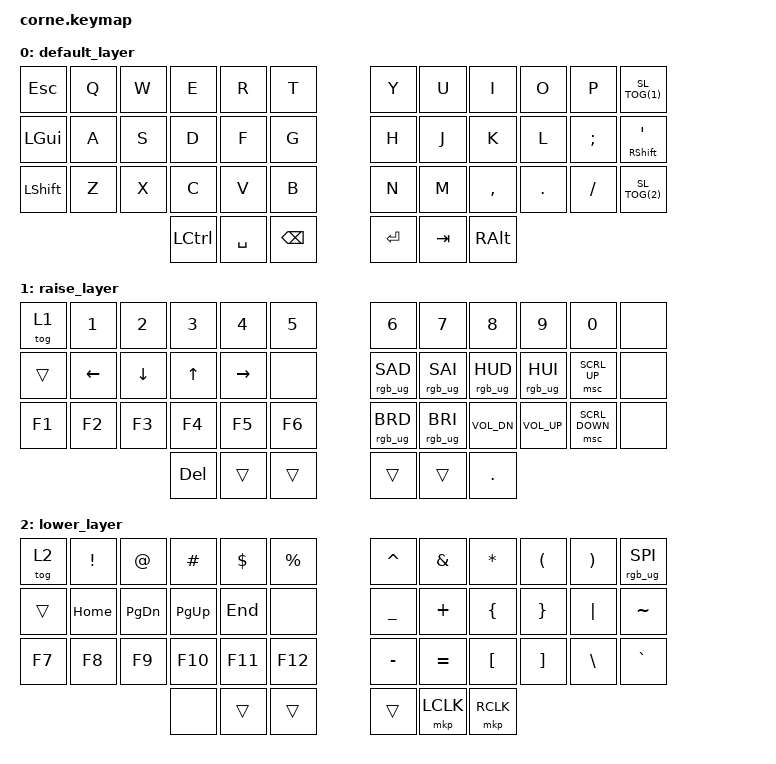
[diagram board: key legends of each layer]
/*
 * Copyright (c) 2020 The ZMK Contributors
 *
 * SPDX-License-Identifier: MIT
 */

#include <behaviors.dtsi>
#include <dt-bindings/zmk/keys.h>
#include <dt-bindings/zmk/bt.h>
#include <dt-bindings/zmk/rgb.h>
#include <dt-bindings/zmk/pointing.h>

#define SL_TOG(layer) &sl_tog layer layer // Macro for "sticky layer" on tap "tog layer" on hold

&mt {
    tapping-term-ms = <250>;
};

&sl {
    release-after-ms = <2000>;
};

&led_strip {
    chain-length = <27>;
};

/ {
    behaviors {
        sl_tog: behavior_sl_tog {
            compatible = "zmk,behavior-hold-tap";
            #binding-cells = <2>;
            flavor = "tap-preferred";
            tapping-term-ms = <300>;
            bindings = <&tog>, <&sl>;
        };
    };

    keymap {
        compatible = "zmk,keymap";

// -----------------------------------------------------------------------------------
// |  ESC |  Q  |  W  |  E  |  R  |  T  |   |  Y  |  U  |  I  |  O  |  P  | L1       |
// |  GUI |  A  |  S  |  D  |  F  |  G  |   |  H  |  J  |  K  |  L  |  ;  | ' > SHFT |
// | SHFT |  Z  |  X  |  C  |  V  |  B  |   |  N  |  M  |  ,  |  .  |  /  | L2       |
//                    | CTL | SPC | BSP |   | ENT | TAB | ALT |
        default_layer { bindings = <
    &kp ESC   &kp Q &kp W &kp E     &kp R     &kp T      &kp Y     &kp U   &kp I     &kp O   &kp P    SL_TOG(1)
    &kp LGUI  &kp A &kp S &kp D     &kp F     &kp G      &kp H     &kp J   &kp K     &kp L   &kp SEMI &mt RSHFT SQT
    &kp LSHFT &kp Z &kp X &kp C     &kp V     &kp B      &kp N     &kp M   &kp COMMA &kp DOT &kp FSLH SL_TOG(2)
                          &kp LCTRL &kp SPACE &kp BSPC   &kp ENTER &kp TAB &kp RALT
        >; };

// -----------------------------------------------------------------------------
// | L0 |  1  |  2  |  3  |  4  |  5  |   |  6  |  7  |  8  |  9  |  0  | xxx |
// |    | LFT | DWN | UP  | RGT | xxx |   | SAD | SAI | HUD | HUI | SCU | xxx |
// | F1 | F2  | F3  | F4  | F5  | F6  |   | BRD | BRI | VDN | VUP | SCD | xxx |
//                  | DEL |     |     |   |     |     |  .  |
        raise_layer { bindings = <
    &tog 1 &kp N1   &kp N2   &kp N3  &kp N4    &kp N5 &kp N6          &kp N7          &kp N8          &kp N9          &kp N0         &none
    &trans &kp LEFT &kp DOWN &kp UP  &kp RIGHT &none  &rgb_ug RGB_SAD &rgb_ug RGB_SAI &rgb_ug RGB_HUD &rgb_ug RGB_HUI &msc SCRL_UP   &none
    &kp F1 &kp F2   &kp F3   &kp F4  &kp F5    &kp F6 &rgb_ug RGB_BRD &rgb_ug RGB_BRI &kp C_VOL_DN    &kp C_VOL_UP    &msc SCRL_DOWN &none
                             &kp DEL &trans    &trans &trans          &trans          &kp DOT
        >; };

// -----------------------------------------------------------------------------
// | L0 |  !  |  @  |  #  |  $  |  %  |   |  ^  |  &  |  *  |  (  |  )  | diag |
// |    | HME | PDN | PUP | END | xxx |   |  _  |  +  |  {  |  }  | "|" |  ~  |
// | F7 | F8  | F9  | F10 | F11 | F12 |   |  -  |  =  |  [  |  ]  |  \  |  `  |
//                  | xxx |     |     |   |     | MB1 | MB2 |
        lower_layer { bindings = <
    &tog 2 &kp EXCL &kp AT    &kp HASH  &kp DLLR &kp PRCNT &kp CARET &kp AMPS  &kp ASTRK &kp LPAR &kp RPAR &rgb_ug RGB_SPI
    &trans &kp HOME &kp PG_DN &kp PG_UP &kp END  &none     &kp UNDER &kp PLUS  &kp LBRC  &kp RBRC &kp PIPE &kp TILDE
    &kp F7 &kp F8   &kp F9    &kp F10   &kp F11  &kp F12   &kp MINUS &kp EQUAL &kp LBKT  &kp RBKT &kp BSLH &kp GRAVE
                              &none     &trans   &trans    &trans    &mkp LCLK &mkp RCLK
        >; };
    };
};
